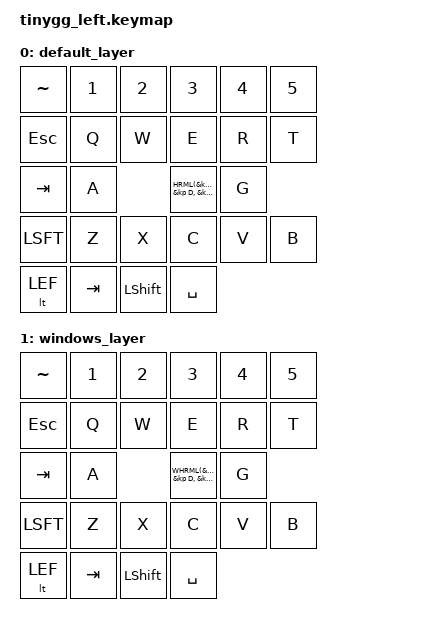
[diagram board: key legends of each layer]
// SPDX-License-Identifier: MIT

#include <behaviors.dtsi>
#include <dt-bindings/zmk/keys.h>
#include <dt-bindings/zmk/bt.h>
#include <dt-bindings/zmk/outputs.h>

// Home row mods macro
#define HRML(k2,k3,k4) &ht LALT k2  &ht LCTRL k3  &ht LGUI k4
#define HRMR(k1,k2,k3) &ht RGUI k1  &ht RCTRL k2  &ht RALT k3

#define MAC 0
#define WIN 1
#define RIG 2
#define LEF 3
#define TRI 4

/ {
    keymap {
        compatible = "zmk,keymap";
        default_layer {
            bindings = <
        // Left half
            &kp TILDE &kp N1     &kp N2     &kp N3     &kp N4     &kp N5
            &kp ESC   &kp Q      &kp W      &kp E      &kp R      &kp T
            &kp TAB   &kp A      HRML(&kp S, &kp D, &kp F) &kp G
            &kp LSFT  &kp Z      &kp X      &kp C      &kp V      &kp B
            &lt LEF &kp TAB  &kp LSHIFT    &kp SPACE
            >;
        };

        windows_layer {
            bindings = <
        // Left half
            &kp TILDE &kp N1     &kp N2     &kp N3     &kp N4     &kp N5
            &kp ESC   &kp Q      &kp W      &kp E      &kp R      &kp T
            &kp TAB   &kp A      WHRML(&kp S, &kp D, &kp F) &kp G
            &kp LSFT  &kp Z      &kp X      &kp C      &kp V      &kp B
            &lt LEF &kp TAB  &kp LSHIFT    &kp SPACE
            >;
        };

        // Additional layers as needed
    };
};
